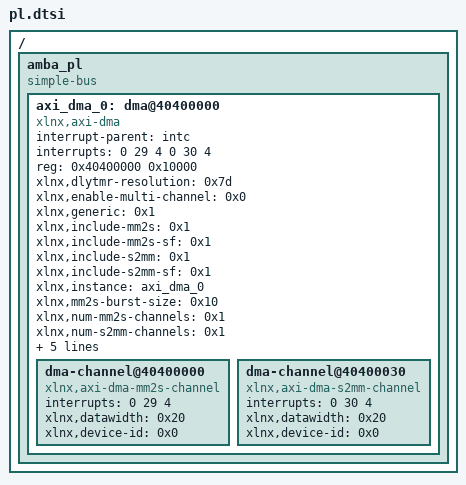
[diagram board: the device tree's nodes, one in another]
/*
 * CAUTION: This file is automatically generated by Xilinx.
 * Version:  
 * Today is: Sun Nov  6 13:46:04 2016
*/


/ {
	amba_pl: amba_pl 
	{
		#address-cells = <1>;
		#size-cells = <1>;
		compatible = "simple-bus";
		ranges ;
		
		axi_dma_0: dma@40400000 
		{
			compatible = "xlnx,axi-dma";
			interrupt-parent = <&intc>;
			interrupts = <0 29 4 0 30 4>;
			reg = <0x40400000 0x10000>;
			
			xlnx,dlytmr-resolution = <0x7d>;
			xlnx,enable-multi-channel = <0x0>;
			xlnx,generic = <0x1>;
			xlnx,include-mm2s = <0x1>;
			xlnx,include-mm2s-sf = <0x1>;
			xlnx,include-s2mm = <0x1>;
			xlnx,include-s2mm-sf = <0x1>;
			xlnx,instance = "axi_dma_0";
			xlnx,mm2s-burst-size = <0x10>;
			xlnx,num-mm2s-channels = <0x1>;
			xlnx,num-s2mm-channels = <0x1>;
			xlnx,prmry-is-aclk-async = <0x0>;
			xlnx,s2mm-burst-size = <0x10>;
			xlnx,sg-include-desc-queue = <0x0>;
			xlnx,sg-length-width = <0x0>;
			xlnx,sg-use-stsapp-length = <0x0>;
			
			dma-channel@40400000 
			{
				compatible = "xlnx,axi-dma-mm2s-channel";
				interrupts = <0 29 4>;
				xlnx,datawidth = <0x20>;
				xlnx,device-id = <0x0>;
			};
			
			dma-channel@40400030 
			{
				compatible = "xlnx,axi-dma-s2mm-channel";
				interrupts = <0 30 4>;
				xlnx,datawidth = <0x20>;
				xlnx,device-id = <0x0>;
			};
		};
	};
};
